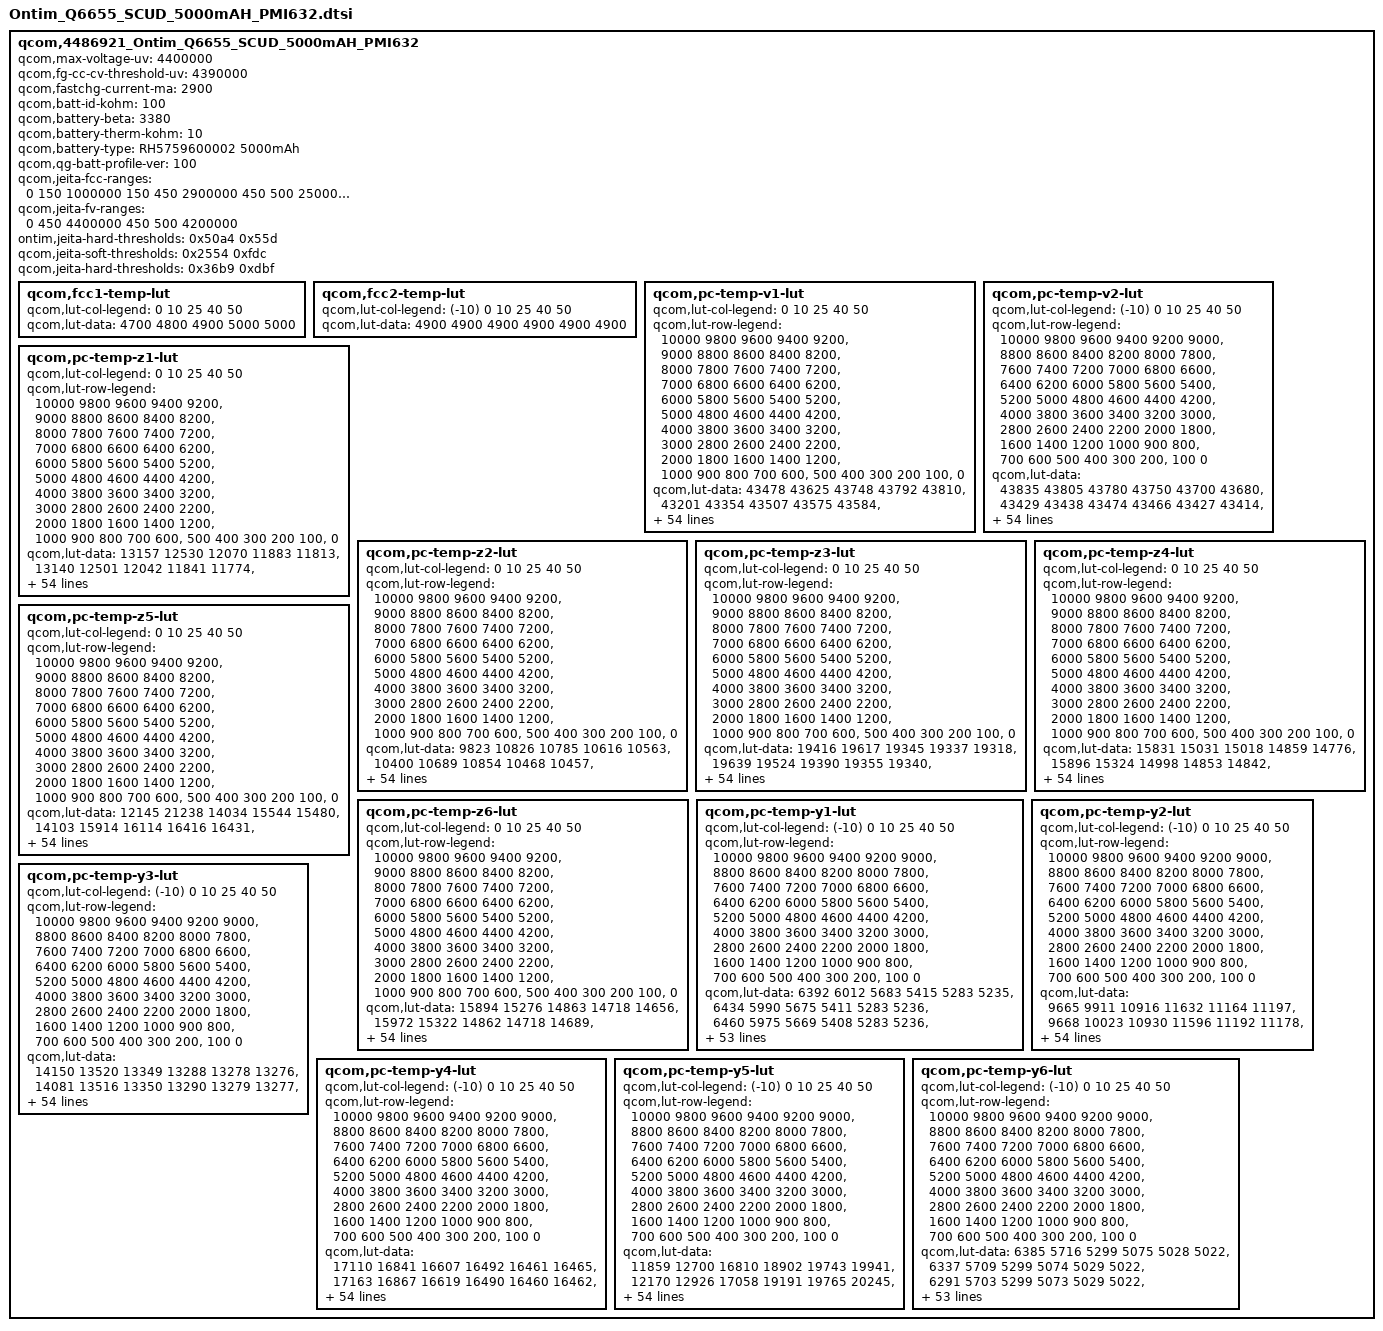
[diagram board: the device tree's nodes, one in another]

qcom,4486921_Ontim_Q6655_SCUD_5000mAH_PMI632 {
    /* 4486921_Ontim_Q6655_SCUD_5000mAH_PMI632_averaged_MasterSlave_Mar20th2020 */
    qcom,max-voltage-uv = <4400000>;
    qcom,fg-cc-cv-threshold-uv = <4390000>;
    qcom,fastchg-current-ma = <2900>;
    qcom,batt-id-kohm = <100>;
    qcom,battery-beta = <3380>;
    qcom,battery-therm-kohm = <10>;
    qcom,battery-type = "RH5759600002 5000mAh";
    qcom,qg-batt-profile-ver = <100>;

	qcom,jeita-fcc-ranges = <0     150   1000000
							 150   450   2900000
							 450   500   2500000>;
	
	qcom,jeita-fv-ranges = <0    450   4400000
							450  500   4200000>;

	/* ontim config jeita for dual 85 test begin */
	/* COLD = -20 DegC, HOT = 85 DegC */
	ontim,jeita-hard-thresholds = <0x50a4 0x55d>;
	/* ontim config jeita for dual 85 test end */

	/* COOL = 15 DegC, WARM = 45 DegC */
	qcom,jeita-soft-thresholds = <0x2554 0xfdc>;
	/* COLD = 0 DegC, HOT = 50 DegC */
	qcom,jeita-hard-thresholds = <0x36b9 0xdbf>;

	qcom,fcc1-temp-lut {
		qcom,lut-col-legend = <0 10 25 40 50>;
		qcom,lut-data = <4700 4800 4900 5000 5000>;
	};

	qcom,fcc2-temp-lut {
		qcom,lut-col-legend = <(-10) 0 10 25 40 50>;
		qcom,lut-data = <4900 4900 4900 4900 4900 4900>;
	};

	qcom,pc-temp-v1-lut {
		qcom,lut-col-legend = <0 10 25 40 50>;
		qcom,lut-row-legend = <10000 9800 9600 9400 9200>,
			<9000 8800 8600 8400 8200>,
			<8000 7800 7600 7400 7200>,
			<7000 6800 6600 6400 6200>,
			<6000 5800 5600 5400 5200>,
			<5000 4800 4600 4400 4200>,
			<4000 3800 3600 3400 3200>,
			<3000 2800 2600 2400 2200>,
			<2000 1800 1600 1400 1200>,
			<1000 900 800 700 600>,
			<500 400 300 200 100>,
			<0>;
		qcom,lut-data = <43478 43625 43748 43792 43810>,
			<43201 43354 43507 43575 43584>,
			<42957 43103 43267 43338 43357>,
			<42722 42867 43028 43100 43128>,
			<42492 42635 42789 42866 42894>,
			<42269 42402 42552 42630 42656>,
			<42053 42174 42320 42396 42422>,
			<41844 41955 42090 42162 42188>,
			<41644 41742 41863 41932 41958>,
			<41453 41537 41639 41706 41730>,
			<41268 41348 41422 41483 41504>,
			<41070 41162 41221 41264 41285>,
			<40855 40960 41023 41048 41069>,
			<40629 40743 40815 40839 40861>,
			<40385 40520 40595 40632 40656>,
			<40117 40282 40384 40434 40458>,
			<39904 40044 40178 40248 40268>,
			<39766 39871 39986 40071 40087>,
			<39656 39754 39831 39903 39913>,
			<39539 39642 39708 39752 39757>,
			<39418 39504 39559 39591 39595>,
			<39298 39350 39300 39363 39382>,
			<39176 39173 39018 39085 39117>,
			<39054 38936 38849 38891 38917>,
			<38925 38715 38736 38772 38793>,
			<38775 38600 38641 38674 38690>,
			<38632 38525 38554 38575 38579>,
			<38530 38463 38478 38481 38470>,
			<38450 38409 38404 38393 38375>,
			<38388 38363 38334 38307 38294>,
			<38342 38320 38270 38231 38222>,
			<38306 38280 38210 38167 38155>,
			<38272 38243 38157 38113 38093>,
			<38241 38208 38111 38059 38033>,
			<38212 38177 38072 38010 37977>,
			<38181 38143 38033 37961 37921>,
			<38150 38109 37995 37912 37865>,
			<38112 38069 37954 37863 37809>,
			<38061 38007 37894 37798 37737>,
			<37997 37919 37806 37707 37644>,
			<37915 37819 37704 37604 37538>,
			<37801 37700 37593 37495 37426>,
			<37666 37564 37465 37371 37300>,
			<37504 37401 37305 37213 37141>,
			<37353 37276 37165 37079 37012>,
			<37250 37171 37073 36994 36934>,
			<37216 37151 37049 36964 36906>,
			<37189 37137 37030 36947 36887>,
			<37161 37109 37015 36926 36865>,
			<37110 37062 36967 36867 36795>,
			<36906 36844 36721 36601 36507>,
			<36464 36401 36285 36164 36067>,
			<35894 35829 35715 35589 35495>,
			<35000 35000 35000 35000 35000>, // 2
			<34500 34500 34500 34500 34500>, // 1
			<34000 34000 34000 34000 34000>; // 0
	};

	qcom,pc-temp-v2-lut {
		qcom,lut-col-legend = <(-10) 0 10 25 40 50>;
		qcom,lut-row-legend = <10000 9800 9600 9400 9200 9000>,
			<8800 8600 8400 8200 8000 7800>,
			<7600 7400 7200 7000 6800 6600>,
			<6400 6200 6000 5800 5600 5400>,
			<5200 5000 4800 4600 4400 4200>,
			<4000 3800 3600 3400 3200 3000>,
			<2800 2600 2400 2200 2000 1800>,
			<1600 1400 1200 1000 900 800>,
			<700 600 500 400 300 200>,
			<100 0>;
		qcom,lut-data = <43835 43805 43780 43750 43700 43680>,
			<43429 43438 43474 43466 43427 43414>,
			<43062 43103 43186 43196 43165 43156>,
			<42738 42808 42918 42940 42915 42909>,
			<42452 42545 42669 42699 42676 42672>,
			<42189 42300 42429 42463 42441 42438>,
			<41939 42071 42190 42228 42207 42205>,
			<41708 41853 41956 41995 41974 41972>,
			<41496 41618 41731 41767 41746 41744>,
			<41291 41354 41511 41543 41521 41518>,
			<41133 41149 41301 41323 41299 41295>,
			<41051 41053 41112 41110 41081 41078>,
			<40987 40977 40929 40901 40867 40863>,
			<40804 40810 40716 40690 40661 40658>,
			<40223 40403 40470 40474 40458 40456>,
			<39691 40001 40224 40265 40264 40263>,
			<39481 39754 39992 40065 40082 40080>,
			<39334 39552 39770 39874 39907 39904>,
			<39174 39353 39568 39706 39737 39734>,
			<39002 39156 39386 39563 39577 39576>,
			<38836 38971 39208 39403 39402 39402>,
			<38674 38801 39020 39172 39173 39175>,
			<38522 38643 38836 38923 38929 38933>,
			<38407 38498 38677 38741 38747 38751>,
			<38320 38356 38537 38602 38605 38608>,
			<38248 38240 38414 38482 38483 38484>,
			<38184 38163 38308 38374 38374 38374>,
			<38127 38103 38214 38278 38277 38276>,
			<38072 38051 38121 38188 38190 38186>,
			<38021 38007 38025 38106 38111 38104>,
			<37972 37967 37949 38031 38039 38030>,
			<37922 37927 37899 37961 37974 37964>,
			<37873 37889 37860 37898 37914 37903>,
			<37823 37849 37823 37840 37849 37836>,
			<37775 37808 37791 37788 37783 37766>,
			<37725 37766 37755 37734 37710 37686>,
			<37668 37720 37715 37676 37624 37585>,
			<37607 37672 37671 37614 37530 37473>,
			<37540 37612 37611 37544 37446 37382>,
			<37464 37539 37530 37468 37370 37308>,
			<37384 37453 37436 37383 37291 37230>,
			<37305 37351 37330 37284 37198 37137>,
			<37225 37234 37211 37172 37093 37032>,
			<37148 37114 37085 37041 36963 36902>,
			<37070 37004 36975 36930 36860 36802>,
			<36985 36919 36897 36877 36813 36757>,
			<36935 36884 36866 36858 36801 36746>,
			<36871 36844 36824 36842 36786 36731>,
			<36793 36785 36758 36810 36756 36699>,
			<36663 36680 36651 36727 36662 36588>,
			<36420 36457 36410 36430 36336 36234>,
			<36019 36045 35956 35934 35840 35735>,
			<35429 35432 35321 35284 35193 35075>,
			<35000 35000 35000 35000 35000 35000>, // 2
			<34500 34500 34500 34500 34500 34500>, // 1
			<33000 33000 33000 33000 33000 33000>; // 0
	};

	qcom,pc-temp-z1-lut {
		qcom,lut-col-legend = <0 10 25 40 50>;
		qcom,lut-row-legend = <10000 9800 9600 9400 9200>,
			<9000 8800 8600 8400 8200>,
			<8000 7800 7600 7400 7200>,
			<7000 6800 6600 6400 6200>,
			<6000 5800 5600 5400 5200>,
			<5000 4800 4600 4400 4200>,
			<4000 3800 3600 3400 3200>,
			<3000 2800 2600 2400 2200>,
			<2000 1800 1600 1400 1200>,
			<1000 900 800 700 600>,
			<500 400 300 200 100>,
			<0>;
		qcom,lut-data = <13157 12530 12070 11883 11813>,
			<13140 12501 12042 11841 11774>,
			<13111 12485 12020 11826 11756>,
			<13093 12473 12009 11816 11745>,
			<13089 12465 11999 11805 11737>,
			<13089 12456 11993 11796 11731>,
			<13080 12450 11990 11790 11727>,
			<13054 12448 11987 11785 11724>,
			<13037 12450 11983 11783 11723>,
			<13042 12450 11976 11783 11724>,
			<13055 12448 11973 11783 11726>,
			<13059 12444 11977 11783 11726>,
			<13032 12436 11981 11784 11725>,
			<12997 12414 11978 11785 11725>,
			<12982 12400 11967 11781 11725>,
			<12973 12401 11960 11778 11725>,
			<12966 12404 11961 11778 11725>,
			<12962 12405 11961 11779 11726>,
			<12960 12402 11963 11780 11727>,
			<12961 12400 11967 11781 11728>,
			<12973 12404 11971 11782 11730>,
			<12982 12414 11974 11783 11730>,
			<12978 12422 11977 11784 11731>,
			<12970 12428 11977 11785 11732>,
			<12967 12432 11980 11787 11734>,
			<12975 12434 11981 11790 11736>,
			<12987 12437 11985 11793 11739>,
			<12994 12439 11990 11796 11741>,
			<13001 12441 11993 11799 11744>,
			<13006 12443 11997 11802 11748>,
			<13010 12446 12000 11806 11751>,
			<13011 12453 12003 11809 11754>,
			<13012 12457 12006 11813 11757>,
			<13022 12458 12009 11818 11760>,
			<13032 12459 12012 11822 11764>,
			<13037 12460 12016 11827 11768>,
			<13051 12465 12024 11831 11771>,
			<13063 12472 12033 11834 11774>,
			<13077 12484 12037 11838 11777>,
			<13091 12501 12041 11843 11781>,
			<13098 12508 12043 11847 11785>,
			<13099 12505 12044 11851 11788>,
			<13103 12504 12047 11855 11792>,
			<13108 12511 12053 11860 11797>,
			<13108 12514 12065 11865 11801>,
			<13107 12526 12064 11868 11801>,
			<13105 12514 12070 11868 11804>,
			<13101 12512 12067 11870 11804>,
			<13099 12512 12071 11873 11808>,
			<13093 12529 12069 11877 11815>,
			<13128 12526 12080 11884 11821>,
			<13109 12561 12083 11893 11827>,
			<13135 12570 12103 11906 11837>,
			<13191 12612 12120 11918 11852>,
			<13191 12612 12120 11918 11852>,
			<13191 12612 12120 11918 11852>;
	};

	qcom,pc-temp-z2-lut {
		qcom,lut-col-legend = <0 10 25 40 50>;
		qcom,lut-row-legend = <10000 9800 9600 9400 9200>,
			<9000 8800 8600 8400 8200>,
			<8000 7800 7600 7400 7200>,
			<7000 6800 6600 6400 6200>,
			<6000 5800 5600 5400 5200>,
			<5000 4800 4600 4400 4200>,
			<4000 3800 3600 3400 3200>,
			<3000 2800 2600 2400 2200>,
			<2000 1800 1600 1400 1200>,
			<1000 900 800 700 600>,
			<500 400 300 200 100>,
			<0>;
		qcom,lut-data = <9823 10826 10785 10616 10563>,
			<10400 10689 10854 10468 10457>,
			<10434 10663 10885 10670 10481>,
			<10443 10648 10860 10762 10515>,
			<10438 10629 10809 10737 10580>,
			<10430 10603 10778 10699 10656>,
			<10427 10577 10947 10675 10664>,
			<10425 10557 11181 10652 10626>,
			<10422 10538 11136 10628 10591>,
			<10420 10530 10825 10592 10574>,
			<10417 10531 10651 10563 10560>,
			<10411 10534 10660 10567 10539>,
			<10377 10551 10676 10588 10511>,
			<10337 10634 10760 10606 10481>,
			<10315 10723 11062 10625 10440>,
			<10298 10794 11232 10638 10401>,
			<10291 10859 11028 10617 10393>,
			<10317 10874 10744 10556 10400>,
			<10365 10782 10704 10532 10411>,
			<10399 10701 10729 10535 10428>,
			<10424 10709 10763 10539 10452>,
			<10442 10724 10817 10599 10485>,
			<10451 10729 10869 10738 10533>,
			<10458 10722 10857 10779 10558>,
			<10467 10714 10777 10653 10547>,
			<10486 10717 10731 10533 10538>,
			<10509 10731 10776 10603 10636>,
			<10524 10741 10839 10785 10884>,
			<10536 10744 10849 10853 10973>,
			<10547 10747 10849 10819 10800>,
			<10562 10750 10848 10766 10593>,
			<10579 10756 10844 10709 10514>,
			<10596 10763 10838 10634 10465>,
			<10616 10773 10836 10613 10426>,
			<10639 10789 10837 10624 10386>,
			<10667 10804 10841 10642 10362>,
			<10701 10821 10859 10676 10392>,
			<10724 10839 10890 10729 10471>,
			<10598 10861 10919 10773 10530>,
			<10411 10886 10953 10811 10576>,
			<10331 10908 10979 10836 10604>,
			<10119 10925 10995 10842 10603>,
			<10052 10948 11007 10843 10600>,
			<10111 10991 11015 10876 10710>,
			<10250 11017 11093 10850 10716>,
			<10447 11294 11123 10766 10566>,
			<10361 11575 11116 10720 10577>,
			<10453 15200 11110 10752 10616>,
			<10322 11622 11121 10784 10628>,
			<10330 15583 11200 10913 10729>,
			<10378 11678 11255 10803 10558>,
			<10084 11144 11126 10631 10375>,
			<9946 10946 11074 10573 10307>,
			<9696 10573 11078 10492 10266>,
			<9696 10573 11078 10492 10266>,
			<9696 10573 11078 10492 10266>;
	};

	qcom,pc-temp-z3-lut {
		qcom,lut-col-legend = <0 10 25 40 50>;
		qcom,lut-row-legend = <10000 9800 9600 9400 9200>,
			<9000 8800 8600 8400 8200>,
			<8000 7800 7600 7400 7200>,
			<7000 6800 6600 6400 6200>,
			<6000 5800 5600 5400 5200>,
			<5000 4800 4600 4400 4200>,
			<4000 3800 3600 3400 3200>,
			<3000 2800 2600 2400 2200>,
			<2000 1800 1600 1400 1200>,
			<1000 900 800 700 600>,
			<500 400 300 200 100>,
			<0>;
		qcom,lut-data = <19416 19617 19345 19337 19318>,
			<19639 19524 19390 19355 19340>,
			<19697 19532 19420 19374 19354>,
			<19714 19548 19429 19386 19366>,
			<19713 19555 19433 19391 19377>,
			<19710 19558 19438 19394 19386>,
			<19705 19559 19447 19396 19390>,
			<19695 19559 19456 19399 19392>,
			<19682 19557 19455 19400 19393>,
			<19669 19554 19445 19397 19392>,
			<19655 19544 19437 19394 19389>,
			<19651 19530 19432 19391 19384>,
			<19655 19526 19427 19387 19378>,
			<19661 19530 19425 19384 19373>,
			<19668 19533 19426 19383 19370>,
			<19680 19534 19426 19382 19367>,
			<19686 19534 19421 19378 19364>,
			<19661 19531 19412 19372 19361>,
			<19619 19500 19405 19366 19358>,
			<19604 19472 19396 19359 19353>,
			<19600 19476 19392 19355 19349>,
			<19598 19489 19402 19357 19349>,
			<19601 19501 19415 19365 19349>,
			<19612 19512 19414 19366 19349>,
			<19624 19519 19401 19352 19337>,
			<19641 19519 19392 19338 19325>,
			<19656 19517 19392 19344 19340>,
			<19658 19515 19393 19360 19387>,
			<19652 19512 19395 19374 19406>,
			<19645 19508 19404 19388 19400>,
			<19636 19504 19412 19398 19391>,
			<19624 19501 19417 19396 19384>,
			<19612 19498 19420 19389 19377>,
			<19600 19495 19420 19382 19370>,
			<19589 19492 19415 19375 19362>,
			<19580 19489 19409 19369 19355>,
			<19572 19486 19405 19363 19350>,
			<19562 19483 19400 19359 19346>,
			<19502 19481 19397 19356 19343>,
			<19422 19478 19395 19355 19341>,
			<19384 19476 19393 19354 19339>,
			<19294 19472 19388 19353 19341>,
			<19263 19467 19385 19352 19344>,
			<19263 19459 19384 19355 19351>,
			<19261 19367 19375 19352 19350>,
			<19261 19394 19370 19338 19335>,
			<19261 19324 19363 19337 19330>,
			<19260 19259 19364 19330 19323>,
			<19261 19260 19347 19327 19319>,
			<19261 19257 19339 19319 19317>,
			<19261 19259 19348 19336 19342>,
			<19262 19260 19357 19343 19352>,
			<19263 19260 19362 19343 19347>,
			<19267 19262 19326 19343 19345>,
			<19267 19262 19326 19343 19345>,
			<19267 19262 19326 19343 19345>;
	};

	qcom,pc-temp-z4-lut {
		qcom,lut-col-legend = <0 10 25 40 50>;
		qcom,lut-row-legend = <10000 9800 9600 9400 9200>,
			<9000 8800 8600 8400 8200>,
			<8000 7800 7600 7400 7200>,
			<7000 6800 6600 6400 6200>,
			<6000 5800 5600 5400 5200>,
			<5000 4800 4600 4400 4200>,
			<4000 3800 3600 3400 3200>,
			<3000 2800 2600 2400 2200>,
			<2000 1800 1600 1400 1200>,
			<1000 900 800 700 600>,
			<500 400 300 200 100>,
			<0>;
		qcom,lut-data = <15831 15031 15018 14859 14776>,
			<15896 15324 14998 14853 14842>,
			<15716 15297 14971 14855 14836>,
			<15553 15163 14937 14853 14828>,
			<15425 15055 14890 14832 14813>,
			<15315 14985 14845 14802 14789>,
			<15228 14927 14798 14780 14770>,
			<15156 14882 14758 14760 14753>,
			<15099 14844 14744 14743 14737>,
			<15057 14817 14738 14727 14722>,
			<15023 14802 14732 14713 14708>,
			<14988 14790 14721 14706 14702>,
			<14951 14771 14710 14700 14699>,
			<14917 14743 14700 14695 14695>,
			<14894 14721 14686 14688 14691>,
			<14875 14713 14679 14682 14687>,
			<14861 14708 14683 14678 14683>,
			<14851 14705 14688 14675 14678>,
			<14842 14712 14684 14672 14674>,
			<14829 14718 14673 14671 14672>,
			<14808 14712 14668 14670 14671>,
			<14786 14704 14717 14697 14692>,
			<14768 14703 14787 14770 14763>,
			<14753 14755 14807 14802 14800>,
			<14747 14812 14814 14810 14804>,
			<14752 14815 14816 14813 14807>,
			<14760 14803 14806 14801 14786>,
			<14763 14790 14787 14767 14723>,
			<14766 14777 14768 14739 14692>,
			<14768 14763 14747 14713 14686>,
			<14764 14750 14729 14694 14683>,
			<14755 14739 14714 14686 14678>,
			<14749 14728 14702 14680 14673>,
			<14745 14718 14696 14678 14671>,
			<14741 14710 14693 14677 14671>,
			<14737 14703 14690 14677 14672>,
			<14731 14696 14688 14676 14672>,
			<14729 14693 14687 14676 14672>,
			<14783 14693 14688 14677 14674>,
			<14860 14695 14693 14687 14686>,
			<14893 14695 14697 14695 14696>,
			<14982 14692 14693 14691 14691>,
			<15007 14690 14688 14685 14683>,
			<14988 14689 14685 14684 14682>,
			<14903 14737 14671 14675 14673>,
			<14890 14687 14657 14665 14663>,
			<14883 14757 14653 14659 14659>,
			<14877 14817 14643 14651 14650>,
			<14873 14812 14648 14636 14634>,
			<14869 14809 14653 14640 14628>,
			<14870 14814 14661 14655 14647>,
			<14888 14825 14661 14659 14649>,
			<14897 14830 14659 14663 14659>,
			<14910 14835 14702 14667 14663>,
			<14910 14835 14702 14667 14663>,
			<14910 14835 14702 14667 14663>;
	};

	qcom,pc-temp-z5-lut {
		qcom,lut-col-legend = <0 10 25 40 50>;
		qcom,lut-row-legend = <10000 9800 9600 9400 9200>,
			<9000 8800 8600 8400 8200>,
			<8000 7800 7600 7400 7200>,
			<7000 6800 6600 6400 6200>,
			<6000 5800 5600 5400 5200>,
			<5000 4800 4600 4400 4200>,
			<4000 3800 3600 3400 3200>,
			<3000 2800 2600 2400 2200>,
			<2000 1800 1600 1400 1200>,
			<1000 900 800 700 600>,
			<500 400 300 200 100>,
			<0>;
		qcom,lut-data = <12145 21238 14034 15544 15480>,
			<14103 15914 16114 16416 16431>,
			<14840 16142 17690 18199 17645>,
			<15284 16843 18555 19428 18988>,
			<15593 17561 19058 20030 20406>,
			<15820 18283 19750 20505 21904>,
			<16024 19034 21564 21161 23085>,
			<16209 19936 23553 22245 24107>,
			<16357 21038 24109 22980 25125>,
			<16450 21564 24037 23657 26463>,
			<16520 21519 24281 24385 27626>,
			<16649 21441 25336 24932 27711>,
			<17001 21781 26472 25568 27294>,
			<17559 23864 27374 26489 27055>,
			<18537 26286 29440 28623 27540>,
			<20253 28795 30594 30451 28488>,
			<21170 31390 29363 30059 29595>,
			<20112 31559 27788 28628 31139>,
			<18442 27017 28051 28091 32232>,
			<18112 22980 29140 28531 32904>,
			<19020 25759 31022 29336 33339>,
			<20507 34214 40091 31156 33013>,
			<22497 41755 50960 34210 31358>,
			<25672 48841 49471 34653 28899>,
			<30277 53861 35619 26474 22692>,
			<41773 52788 26148 18694 16962>,
			<53336 47066 24058 18685 19626>,
			<54645 42161 22892 19837 28808>,
			<52142 39114 23095 21559 32849>,
			<48972 36863 25030 26909 32658>,
			<45318 36009 27697 31890 32367>,
			<40843 35548 32163 33239 32943>,
			<37225 35363 37144 34013 33954>,
			<34111 35793 39413 34667 34268>,
			<31632 36736 40964 35353 33965>,
			<30206 37589 41603 35738 33534>,
			<29224 38490 41166 35503 33208>,
			<28232 39216 40250 34788 32862>,
			<24904 39629 39170 33810 32037>,
			<20832 39957 37480 32041 29011>,
			<18769 39912 35419 30016 26412>,
			<13498 37813 32188 27763 25983>,
			<11766 36338 30113 26161 26112>,
			<11861 34870 30420 27845 29608>,
			<12343 24134 31578 28021 30278>,
			<12352 26834 32399 23627 23379>,
			<12309 19660 29311 23463 21448>,
			<12275 12224 31067 21938 20759>,
			<12282 12210 23414 24224 23196>,
			<12314 12216 21275 21260 23958>,
			<12366 12289 22238 22419 27087>,
			<12259 12200 22077 20526 25739>,
			<12114 12089 22608 19247 20506>,
			<11975 11982 15299 17890 17978>,
			<11975 11982 15299 17890 17978>,
			<11975 11982 15299 17890 17978>;
	};

	qcom,pc-temp-z6-lut {
		qcom,lut-col-legend = <0 10 25 40 50>;
		qcom,lut-row-legend = <10000 9800 9600 9400 9200>,
			<9000 8800 8600 8400 8200>,
			<8000 7800 7600 7400 7200>,
			<7000 6800 6600 6400 6200>,
			<6000 5800 5600 5400 5200>,
			<5000 4800 4600 4400 4200>,
			<4000 3800 3600 3400 3200>,
			<3000 2800 2600 2400 2200>,
			<2000 1800 1600 1400 1200>,
			<1000 900 800 700 600>,
			<500 400 300 200 100>,
			<0>;
		qcom,lut-data = <15894 15276 14863 14718 14656>,
			<15972 15322 14862 14718 14689>,
			<15874 15300 14858 14725 14692>,
			<15779 15227 14849 14728 14693>,
			<15696 15164 14825 14720 14691>,
			<15619 15119 14801 14707 14685>,
			<15555 15081 14784 14698 14680>,
			<15499 15050 14769 14690 14673>,
			<15452 15025 14758 14682 14666>,
			<15414 15002 14748 14674 14660>,
			<15382 14984 14740 14666 14653>,
			<15351 14967 14732 14661 14647>,
			<15319 14948 14725 14656 14642>,
			<15291 14926 14718 14652 14638>,
			<15274 14911 14710 14648 14634>,
			<15261 14906 14705 14644 14630>,
			<15248 14903 14702 14639 14626>,
			<15225 14897 14700 14635 14623>,
			<15199 14884 14696 14631 14620>,
			<15182 14875 14688 14627 14616>,
			<15168 14876 14684 14624 14613>,
			<15159 14881 14712 14638 14622>,
			<15160 14890 14749 14674 14654>,
			<15161 14920 14755 14687 14668>,
			<15164 14948 14753 14684 14665>,
			<15177 14950 14752 14679 14661>,
			<15192 14946 14747 14676 14659>,
			<15195 14942 14741 14671 14658>,
			<15195 14935 14736 14668 14656>,
			<15195 14928 14733 14666 14651>,
			<15191 14922 14730 14663 14646>,
			<15181 14918 14727 14659 14641>,
			<15174 14913 14725 14654 14636>,
			<15170 14910 14723 14649 14631>,
			<15166 14907 14720 14646 14627>,
			<15163 14905 14717 14643 14624>,
			<15161 14903 14715 14640 14621>,
			<15159 14903 14714 14638 14619>,
			<15159 14904 14714 14638 14619>,
			<15158 14909 14717 14642 14623>,
			<15158 14912 14718 14645 14626>,
			<15157 14914 14716 14643 14626>,
			<15157 14915 14715 14641 14625>,
			<15159 14916 14716 14643 14628>,
			<15139 14902 14709 14640 14625>,
			<15133 14897 14702 14629 14613>,
			<15131 14893 14698 14626 14609>,
			<15130 14889 14694 14619 14601>,
			<15129 14889 14689 14611 14592>,
			<15131 14891 14689 14610 14590>,
			<15141 14900 14701 14627 14612>,
			<15156 14912 14709 14635 14622>,
			<15174 14922 14715 14639 14625>,
			<15199 14937 14721 14645 14630>,
			<15199 14937 14721 14645 14630>,
			<15199 14937 14721 14645 14630>;
	};

	qcom,pc-temp-y1-lut {
		qcom,lut-col-legend = <(-10) 0 10 25 40 50>;
		qcom,lut-row-legend = <10000 9800 9600 9400 9200 9000>,
			<8800 8600 8400 8200 8000 7800>,
			<7600 7400 7200 7000 6800 6600>,
			<6400 6200 6000 5800 5600 5400>,
			<5200 5000 4800 4600 4400 4200>,
			<4000 3800 3600 3400 3200 3000>,
			<2800 2600 2400 2200 2000 1800>,
			<1600 1400 1200 1000 900 800>,
			<700 600 500 400 300 200>,
			<100 0>;
		qcom,lut-data = <6392 6012 5683 5415 5283 5235>,
			<6434 5990 5675 5411 5283 5236>,
			<6460 5975 5669 5408 5283 5236>,
			<6474 5967 5664 5404 5283 5236>,
			<6480 5963 5660 5401 5282 5236>,
			<6479 5961 5659 5399 5281 5235>,
			<6465 5964 5660 5398 5280 5234>,
			<6444 5971 5662 5397 5279 5232>,
			<6441 5971 5661 5397 5278 5231>,
			<6453 5966 5657 5396 5275 5230>,
			<6463 5963 5653 5395 5274 5229>,
			<6466 5970 5651 5393 5273 5229>,
			<6469 5981 5650 5391 5273 5228>,
			<6469 5984 5651 5390 5272 5228>,
			<6469 5980 5659 5391 5269 5228>,
			<6470 5977 5665 5392 5268 5228>,
			<6472 5979 5666 5395 5269 5228>,
			<6475 5982 5667 5398 5271 5229>,
			<6477 5986 5666 5399 5271 5229>,
			<6482 5995 5666 5396 5271 5229>,
			<6485 6000 5666 5395 5270 5230>,
			<6481 5996 5665 5396 5271 5230>,
			<6473 5989 5665 5399 5272 5231>,
			<6468 5988 5665 5401 5274 5233>,
			<6460 5991 5666 5402 5276 5234>,
			<6453 5993 5667 5404 5278 5235>,
			<6455 5991 5671 5407 5281 5237>,
			<6459 5987 5677 5411 5284 5240>,
			<6461 5985 5678 5414 5286 5242>,
			<6465 5987 5677 5417 5289 5245>,
			<6470 5988 5676 5419 5291 5247>,
			<6471 5987 5677 5420 5294 5250>,
			<6471 5984 5678 5422 5297 5253>,
			<6470 5983 5677 5425 5300 5255>,
			<6466 5979 5675 5429 5303 5256>,
			<6463 5977 5673 5431 5306 5258>,
			<6470 5980 5677 5431 5308 5260>,
			<6482 5988 5686 5429 5309 5263>,
			<6486 5991 5688 5430 5311 5265>,
			<6479 5984 5687 5433 5313 5267>,
			<6471 5978 5686 5436 5315 5269>,
			<6468 5982 5683 5436 5316 5271>,
			<6468 5994 5681 5437 5317 5272>,
			<6467 6004 5683 5443 5322 5276>,
			<6469 6013 5691 5451 5330 5281>,
			<6494 6025 5692 5452 5335 5284>,
			<6510 6038 5689 5462 5333 5283>,
			<6523 6035 5705 5458 5333 5282>,
			<6553 6032 5705 5459 5330 5282>,
			<6546 6036 5711 5457 5331 5284>,
			<6521 6033 5717 5465 5337 5287>,
			<6535 6040 5723 5472 5342 5294>,
			<6566 6066 5730 5475 5353 5300>,
			<6620 6097 5762 5506 5365 5310>,
			<6620 6097 5762 5506 5365 5310>,
			<6620 6097 5762 5506 5365 5310>;
	};

	qcom,pc-temp-y2-lut {
		qcom,lut-col-legend = <(-10) 0 10 25 40 50>;
		qcom,lut-row-legend = <10000 9800 9600 9400 9200 9000>,
			<8800 8600 8400 8200 8000 7800>,
			<7600 7400 7200 7000 6800 6600>,
			<6400 6200 6000 5800 5600 5400>,
			<5200 5000 4800 4600 4400 4200>,
			<4000 3800 3600 3400 3200 3000>,
			<2800 2600 2400 2200 2000 1800>,
			<1600 1400 1200 1000 900 800>,
			<700 600 500 400 300 200>,
			<100 0>;
		qcom,lut-data = <9665 9911 10916 11632 11164 11197>,
			<9668 10023 10930 11596 11192 11178>,
			<9670 10128 10942 11550 11205 11156>,
			<9673 10217 10953 11501 11205 11132>,
			<9676 10279 10960 11455 11196 11105>,
			<9677 10302 10964 11421 11182 11076>,
			<9679 10279 10964 11392 11138 11042>,
			<9680 10241 10961 11365 11082 11007>,
			<9679 10288 10956 11348 11073 10984>,
			<9676 10625 10942 11337 11085 10966>,
			<9673 10865 10934 11324 11093 10956>,
			<9674 10782 10959 11291 11080 10951>,
			<9675 10634 11019 11254 11062 10949>,
			<9675 10619 11104 11255 11066 10949>,
			<9673 10761 11253 11299 11104 10949>,
			<9671 10888 11347 11358 11153 10952>,
			<9670 10760 11355 11426 11202 10992>,
			<9669 10478 11360 11509 11264 11078>,
			<9669 10353 11372 11599 11359 11182>,
			<9669 10009 11403 11707 11522 11338>,
			<9669 9731 11436 11762 11615 11425>,
			<9669 9714 11464 11720 11573 11379>,
			<9668 9706 11492 11655 11493 11300>,
			<9668 9701 11519 11645 11440 11276>,
			<9668 9696 11547 11657 11398 11271>,
			<9667 9692 11571 11674 11378 11271>,
			<9667 9690 11594 11709 11394 11289>,
			<9666 9688 11613 11756 11431 11323>,
			<9666 9685 11618 11791 11471 11357>,
			<9666 9681 11618 11822 11524 11397>,
			<9665 9678 11618 11841 11580 11428>,
			<9665 9676 11594 11850 11653 11451>,
			<9665 9673 11543 11855 11723 11473>,
			<9665 9671 11497 11857 11734 11481>,
			<9664 9669 11452 11861 11719 11484>,
			<9664 9668 11403 11862 11697 11478>,
			<9664 9667 11360 11843 11643 11445>,
			<9664 9666 11306 11809 11566 11401>,
			<9664 9665 11108 11775 11531 11389>,
			<9663 9664 10359 11735 11511 11400>,
			<9663 9663 9806 11695 11507 11407>,
			<9663 9663 9745 11657 11551 11396>,
			<9663 9662 9715 11612 11592 11370>,
			<9663 9662 9700 11535 11479 11258>,
			<9662 9661 9689 11444 11321 11119>,
			<9662 9661 9687 11442 11260 11043>,
			<9662 9661 9683 11400 11331 11079>,
			<9662 9661 9680 11373 11360 11147>,
			<9662 9661 9677 11393 11362 11186>,
			<9661 9660 9676 11413 11376 11150>,
			<9661 9660 9675 11328 11316 11002>,
			<9660 9659 9672 11219 11211 10906>,
			<9660 9659 9667 11082 11110 10830>,
			<9658 9659 9663 10994 10976 10739>,
			<9658 9659 9663 10994 10976 10739>,
			<9658 9659 9663 10994 10976 10739>;
	};

	qcom,pc-temp-y3-lut {
		qcom,lut-col-legend = <(-10) 0 10 25 40 50>;
		qcom,lut-row-legend = <10000 9800 9600 9400 9200 9000>,
			<8800 8600 8400 8200 8000 7800>,
			<7600 7400 7200 7000 6800 6600>,
			<6400 6200 6000 5800 5600 5400>,
			<5200 5000 4800 4600 4400 4200>,
			<4000 3800 3600 3400 3200 3000>,
			<2800 2600 2400 2200 2000 1800>,
			<1600 1400 1200 1000 900 800>,
			<700 600 500 400 300 200>,
			<100 0>;
		qcom,lut-data = <14150 13520 13349 13288 13278 13276>,
			<14081 13516 13350 13290 13279 13277>,
			<14014 13514 13351 13291 13280 13278>,
			<13953 13512 13352 13292 13280 13278>,
			<13898 13512 13353 13293 13281 13279>,
			<13852 13512 13354 13293 13281 13280>,
			<13819 13517 13356 13294 13282 13280>,
			<13790 13526 13357 13294 13282 13281>,
			<13739 13527 13359 13295 13282 13281>,
			<13643 13517 13359 13295 13283 13281>,
			<13584 13501 13360 13296 13284 13282>,
			<13597 13465 13363 13298 13284 13282>,
			<13620 13420 13366 13300 13284 13283>,
			<13620 13412 13364 13300 13285 13283>,
			<13584 13423 13350 13300 13288 13283>,
			<13552 13431 13341 13300 13291 13283>,
			<13544 13422 13341 13300 13291 13285>,
			<13539 13401 13342 13299 13292 13287>,
			<13539 13389 13341 13300 13292 13288>,
			<13547 13382 13336 13300 13291 13288>,
			<13554 13377 13330 13301 13290 13288>,
			<13552 13371 13326 13298 13287 13285>,
			<13549 13363 13322 13292 13283 13280>,
			<13549 13358 13318 13290 13281 13279>,
			<13557 13349 13314 13290 13280 13278>,
			<13571 13341 13311 13289 13279 13278>,
			<13588 13343 13311 13289 13279 13277>,
			<13611 13347 13310 13288 13278 13277>,
			<13634 13355 13309 13288 13278 13276>,
			<13657 13372 13302 13287 13278 13276>,
			<13680 13394 13297 13286 13278 13275>,
			<13704 13416 13299 13286 13279 13276>,
			<13730 13440 13303 13287 13279 13276>,
			<13758 13466 13306 13287 13280 13277>,
			<13794 13494 13309 13288 13280 13278>,
			<13830 13524 13312 13288 13280 13278>,
			<13862 13559 13314 13288 13280 13277>,
			<13892 13600 13317 13288 13278 13276>,
			<13924 13643 13318 13288 13278 13276>,
			<13959 13691 13321 13288 13279 13278>,
			<13996 13741 13322 13288 13280 13280>,
			<14033 13791 13325 13289 13281 13280>,
			<14073 13842 13331 13290 13282 13281>,
			<14116 13904 13345 13290 13280 13279>,
			<14166 13969 13367 13290 13279 13279>,
			<14180 13990 13378 13292 13282 13283>,
			<14162 13988 13394 13293 13287 13286>,
			<14217 14034 13414 13299 13290 13288>,
			<14272 14082 13439 13304 13292 13290>,
			<14330 14124 13469 13308 13292 13288>,
			<14398 14161 13489 13303 13288 13283>,
			<14481 14218 13512 13303 13286 13284>,
			<14584 14319 13598 13309 13292 13287>,
			<14809 14435 13730 13321 13297 13295>,
			<14809 14435 13730 13321 13297 13295>,
			<14809 14435 13730 13321 13297 13295>;
	};

	qcom,pc-temp-y4-lut {
		qcom,lut-col-legend = <(-10) 0 10 25 40 50>;
		qcom,lut-row-legend = <10000 9800 9600 9400 9200 9000>,
			<8800 8600 8400 8200 8000 7800>,
			<7600 7400 7200 7000 6800 6600>,
			<6400 6200 6000 5800 5600 5400>,
			<5200 5000 4800 4600 4400 4200>,
			<4000 3800 3600 3400 3200 3000>,
			<2800 2600 2400 2200 2000 1800>,
			<1600 1400 1200 1000 900 800>,
			<700 600 500 400 300 200>,
			<100 0>;
		qcom,lut-data = <17110 16841 16607 16492 16461 16465>,
			<17163 16867 16619 16490 16460 16462>,
			<17198 16895 16636 16489 16459 16460>,
			<17218 16920 16653 16488 16459 16458>,
			<17227 16938 16666 16487 16460 16457>,
			<17229 16946 16672 16487 16460 16457>,
			<17216 16941 16670 16488 16462 16458>,
			<17194 16933 16667 16490 16464 16459>,
			<17213 16929 16667 16493 16466 16460>,
			<17371 16926 16671 16499 16469 16462>,
			<17508 16924 16677 16504 16471 16464>,
			<17549 17074 16697 16508 16476 16467>,
			<17575 17335 16730 16513 16481 16470>,
			<17529 17354 16760 16520 16485 16474>,
			<17177 17066 16793 16535 16488 16479>,
			<16907 16843 16810 16552 16493 16485>,
			<16905 16833 16777 16570 16502 16491>,
			<16910 16832 16717 16589 16515 16498>,
			<16903 16825 16684 16606 16533 16510>,
			<16848 16805 16668 16623 16562 16536>,
			<16788 16779 16650 16631 16578 16551>,
			<16750 16745 16615 16584 16546 16527>,
			<16720 16702 16576 16509 16491 16485>,
			<16712 16667 16555 16483 16469 16467>,
			<16712 16634 16544 16473 16461 16459>,
			<16711 16615 16536 16470 16457 16455>,
			<16711 16620 16529 16471 16459 16457>,
			<16710 16631 16523 16474 16463 16460>,
			<16710 16634 16517 16477 16468 16464>,
			<16713 16632 16510 16482 16475 16471>,
			<16717 16631 16506 16487 16483 16479>,
			<16721 16632 16506 16490 16492 16490>,
			<16728 16636 16508 16492 16501 16500>,
			<16733 16642 16511 16493 16503 16502>,
			<16737 16650 16519 16493 16501 16502>,
			<16739 16660 16528 16493 16497 16502>,
			<16740 16666 16537 16489 16484 16488>,
			<16741 16671 16548 16483 16466 16465>,
			<16741 16674 16562 16481 16463 16461>,
			<16740 16675 16584 16480 16466 16466>,
			<16738 16676 16600 16480 16469 16472>,
			<16741 16673 16607 16484 16472 16476>,
			<16751 16663 16611 16488 16474 16478>,
			<16765 16654 16608 16487 16461 16458>,
			<16787 16651 16611 16487 16456 16451>,
			<16790 16656 16614 16487 16467 16469>,
			<16775 16659 16626 16502 16484 16494>,
			<16795 16680 16653 16521 16512 16527>,
			<16823 16712 16694 16552 16546 16559>,
			<16837 16752 16738 16578 16553 16551>,
			<16827 16764 16744 16537 16479 16476>,
			<16817 16753 16728 16522 16473 16471>,
			<16820 16738 16746 16539 16477 16472>,
			<16893 16746 16817 16570 16489 16478>,
			<16893 16746 16817 16570 16489 16478>,
			<16893 16746 16817 16570 16489 16478>;
	};

	qcom,pc-temp-y5-lut {
		qcom,lut-col-legend = <(-10) 0 10 25 40 50>;
		qcom,lut-row-legend = <10000 9800 9600 9400 9200 9000>,
			<8800 8600 8400 8200 8000 7800>,
			<7600 7400 7200 7000 6800 6600>,
			<6400 6200 6000 5800 5600 5400>,
			<5200 5000 4800 4600 4400 4200>,
			<4000 3800 3600 3400 3200 3000>,
			<2800 2600 2400 2200 2000 1800>,
			<1600 1400 1200 1000 900 800>,
			<700 600 500 400 300 200>,
			<100 0>;
		qcom,lut-data = <11859 12700 16810 18902 19743 19941>,
			<12170 12926 17058 19191 19765 20245>,
			<12472 13300 17383 19310 19683 20403>,
			<12764 13800 17718 19302 19513 20447>,
			<13042 14404 17998 19204 19268 20412>,
			<13305 15090 18154 19056 18963 20330>,
			<13604 16095 18202 18714 18304 19903>,
			<13863 17086 18234 18176 17457 19159>,
			<13768 17035 18314 17625 17030 18570>,
			<12871 15548 18493 16982 16784 18056>,
			<12222 14489 18599 16501 16531 17559>,
			<14864 14973 17387 16284 16019 17061>,
			<19546 16232 15454 16176 15465 16570>,
			<20167 18113 15287 15974 15449 16080>,
			<16530 21882 16753 15295 15916 15528>,
			<13747 24338 18525 14872 16226 15251>,
			<13797 22361 20298 14982 16019 15375>,
			<14032 18504 22007 15285 15688 15643>,
			<14366 16906 22826 16206 15715 15907>,
			<15022 16222 23300 19225 16367 16246>,
			<15476 15884 23530 21678 17357 16774>,
			<14873 16156 23584 22853 19502 18717>,
			<13569 16661 23601 23750 22015 21257>,
			<12968 16514 23354 23933 22377 21750>,
			<12742 14969 22060 23871 21598 21623>,
			<12631 13466 21174 23667 20773 21414>,
			<12687 12880 22297 23162 19728 20464>,
			<12837 12478 24153 22496 18560 18902>,
			<12892 12415 23850 21978 18354 17887>,
			<12947 12682 19662 21466 18453 17096>,
			<12993 13004 16731 21226 18626 16727>,
			<12987 13215 17150 21757 19110 16994>,
			<12990 13395 18057 22761 19981 17653>,
			<13068 13505 18836 23606 21097 18645>,
			<13318 13557 19650 24690 22823 20567>,
			<13554 13618 20152 25236 23802 21729>,
			<13649 13874 20266 24875 23138 21409>,
			<13737 14307 20308 24110 21917 20873>,
			<13738 14447 19833 23246 21307 20929>,
			<13604 14433 17022 22074 20981 22002>,
			<13420 14407 14760 21072 20914 22911>,
			<13207 14342 14315 20494 21673 23186>,
			<12987 14209 14120 19929 22404 23310>,
			<12991 14013 14175 19026 20779 22292>,
			<13053 13799 14110 18442 18772 20260>,
			<13313 13723 14035 18597 17588 17657>,
			<13539 13918 14322 17312 18368 17366>,
			<13636 14040 14261 18278 18271 16769>,
			<13914 14158 14391 18813 17874 16551>,
			<14302 14495 15510 19407 17490 16124>,
			<14472 14530 16373 19103 19629 16852>,
			<14247 14419 15235 19521 18226 16955>,
			<13959 14303 14505 19138 20059 16949>,
			<13432 14192 13759 21084 22299 22773>,
			<13432 14192 13759 21084 22299 22773>,
			<13432 14192 13759 21084 22299 22773>;
	};

	qcom,pc-temp-y6-lut {
		qcom,lut-col-legend = <(-10) 0 10 25 40 50>;
		qcom,lut-row-legend = <10000 9800 9600 9400 9200 9000>,
			<8800 8600 8400 8200 8000 7800>,
			<7600 7400 7200 7000 6800 6600>,
			<6400 6200 6000 5800 5600 5400>,
			<5200 5000 4800 4600 4400 4200>,
			<4000 3800 3600 3400 3200 3000>,
			<2800 2600 2400 2200 2000 1800>,
			<1600 1400 1200 1000 900 800>,
			<700 600 500 400 300 200>,
			<100 0>;
		qcom,lut-data = <6385 5716 5299 5075 5028 5022>,
			<6337 5709 5299 5074 5029 5022>,
			<6291 5703 5299 5073 5029 5022>,
			<6247 5697 5297 5072 5030 5022>,
			<6207 5691 5295 5072 5030 5023>,
			<6170 5685 5292 5072 5031 5023>,
			<6134 5679 5287 5072 5031 5024>,
			<6103 5673 5282 5072 5032 5024>,
			<6080 5664 5279 5072 5032 5025>,
			<6061 5647 5276 5073 5033 5026>,
			<6051 5636 5275 5074 5035 5026>,
			<6064 5658 5280 5076 5036 5028>,
			<6086 5696 5287 5078 5037 5029>,
			<6074 5696 5289 5081 5039 5030>,
			<5954 5633 5287 5084 5042 5032>,
			<5861 5575 5285 5088 5045 5034>,
			<5860 5554 5276 5094 5049 5036>,
			<5862 5540 5261 5100 5052 5040>,
			<5861 5529 5250 5104 5057 5044>,
			<5852 5518 5241 5109 5065 5052>,
			<5841 5508 5232 5111 5068 5056>,
			<5832 5498 5219 5095 5057 5046>,
			<5823 5488 5205 5070 5038 5030>,
			<5822 5482 5198 5062 5031 5024>,
			<5829 5478 5193 5059 5027 5021>,
			<5841 5475 5191 5058 5026 5020>,
			<5854 5482 5192 5059 5026 5020>,
			<5871 5499 5194 5060 5028 5021>,
			<5888 5518 5194 5061 5029 5022>,
			<5906 5537 5193 5063 5031 5024>,
			<5925 5558 5192 5064 5034 5026>,
			<5945 5582 5196 5066 5038 5030>,
			<5966 5607 5205 5068 5041 5033>,
			<5989 5634 5216 5070 5042 5034>,
			<6016 5662 5228 5071 5042 5035>,
			<6043 5693 5241 5072 5041 5036>,
			<6068 5726 5256 5072 5038 5031>,
			<6092 5760 5272 5071 5032 5024>,
			<6118 5797 5289 5072 5031 5023>,
			<6144 5837 5306 5073 5033 5026>,
			<6172 5877 5325 5074 5035 5030>,
			<6203 5915 5347 5078 5037 5031>,
			<6238 5954 5374 5082 5038 5032>,
			<6277 6001 5407 5085 5034 5026>,
			<6321 6052 5449 5090 5033 5024>,
			<6337 6071 5463 5092 5040 5033>,
			<6324 6072 5485 5098 5048 5043>,
			<6372 6114 5517 5110 5058 5054>,
			<6423 6160 5555 5123 5069 5064>,
			<6475 6204 5594 5133 5071 5061>,
			<6527 6238 5616 5119 5047 5036>,
			<6593 6282 5644 5121 5046 5036>,
			<6687 6358 5738 5139 5052 5039>,
			<6907 6459 5874 5169 5061 5049>,
			<6907 6459 5874 5169 5061 5049>,
			<6907 6459 5874 5169 5061 5049>;
	};

};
